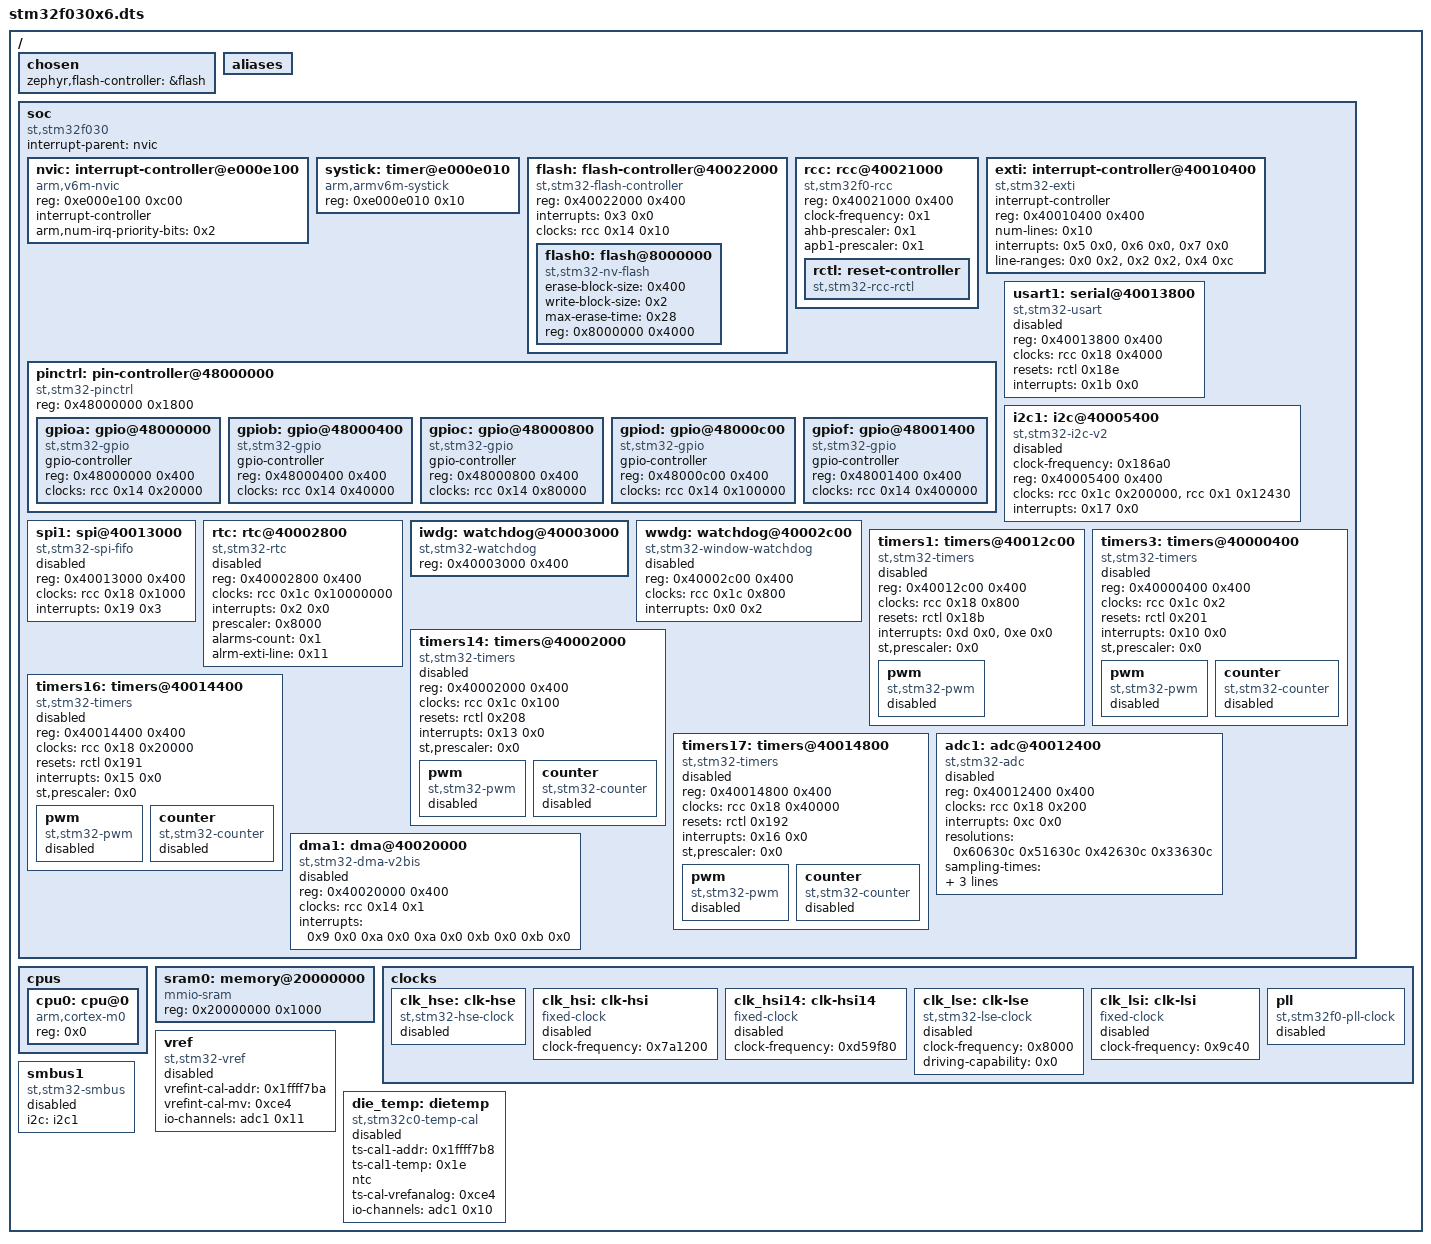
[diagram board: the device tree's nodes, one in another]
/dts-v1/;

/ {
	#address-cells = < 0x1 >;
	#size-cells = < 0x1 >;
	chosen {
		zephyr,flash-controller = &flash;
	};
	aliases {
	};
	soc {
		#address-cells = < 0x1 >;
		#size-cells = < 0x1 >;
		compatible = "st,stm32f030", "st,stm32f0", "simple-bus";
		interrupt-parent = < &nvic >;
		ranges;
		nvic: interrupt-controller@e000e100 {
			#address-cells = < 0x1 >;
			compatible = "arm,v6m-nvic";
			reg = < 0xe000e100 0xc00 >;
			interrupt-controller;
			#interrupt-cells = < 0x2 >;
			arm,num-irq-priority-bits = < 0x2 >;
			phandle = < 0x1 >;
		};
		systick: timer@e000e010 {
			compatible = "arm,armv6m-systick";
			reg = < 0xe000e010 0x10 >;
		};
		flash: flash-controller@40022000 {
			compatible = "st,stm32-flash-controller", "st,stm32f1-flash-controller";
			reg = < 0x40022000 0x400 >;
			interrupts = < 0x3 0x0 >;
			clocks = < &rcc 0x14 0x10 >;
			#address-cells = < 0x1 >;
			#size-cells = < 0x1 >;
			flash0: flash@8000000 {
				compatible = "st,stm32-nv-flash", "soc-nv-flash";
				erase-block-size = < 0x400 >;
				write-block-size = < 0x2 >;
				max-erase-time = < 0x28 >;
				reg = < 0x8000000 0x4000 >;
			};
		};
		rcc: rcc@40021000 {
			compatible = "st,stm32f0-rcc";
			#clock-cells = < 0x2 >;
			reg = < 0x40021000 0x400 >;
			clock-frequency = < 0x1 >;
			ahb-prescaler = < 0x1 >;
			apb1-prescaler = < 0x1 >;
			phandle = < 0x2 >;
			rctl: reset-controller {
				compatible = "st,stm32-rcc-rctl";
				#reset-cells = < 0x1 >;
				phandle = < 0x3 >;
			};
		};
		exti: interrupt-controller@40010400 {
			compatible = "st,stm32-exti";
			interrupt-controller;
			#interrupt-cells = < 0x1 >;
			#address-cells = < 0x1 >;
			reg = < 0x40010400 0x400 >;
			num-lines = < 0x10 >;
			interrupts = < 0x5 0x0 >, < 0x6 0x0 >, < 0x7 0x0 >;
			interrupt-names = "line0-1", "line2-3", "line4-15";
			line-ranges = < 0x0 0x2 >, < 0x2 0x2 >, < 0x4 0xc >;
		};
		pinctrl: pin-controller@48000000 {
			compatible = "st,stm32-pinctrl";
			#address-cells = < 0x1 >;
			#size-cells = < 0x1 >;
			reg = < 0x48000000 0x1800 >;
			gpioa: gpio@48000000 {
				compatible = "st,stm32-gpio";
				gpio-controller;
				#gpio-cells = < 0x2 >;
				reg = < 0x48000000 0x400 >;
				clocks = < &rcc 0x14 0x20000 >;
			};
			gpiob: gpio@48000400 {
				compatible = "st,stm32-gpio";
				gpio-controller;
				#gpio-cells = < 0x2 >;
				reg = < 0x48000400 0x400 >;
				clocks = < &rcc 0x14 0x40000 >;
			};
			gpioc: gpio@48000800 {
				compatible = "st,stm32-gpio";
				gpio-controller;
				#gpio-cells = < 0x2 >;
				reg = < 0x48000800 0x400 >;
				clocks = < &rcc 0x14 0x80000 >;
			};
			gpiod: gpio@48000c00 {
				compatible = "st,stm32-gpio";
				gpio-controller;
				#gpio-cells = < 0x2 >;
				reg = < 0x48000c00 0x400 >;
				clocks = < &rcc 0x14 0x100000 >;
			};
			gpiof: gpio@48001400 {
				compatible = "st,stm32-gpio";
				gpio-controller;
				#gpio-cells = < 0x2 >;
				reg = < 0x48001400 0x400 >;
				clocks = < &rcc 0x14 0x400000 >;
			};
		};
		usart1: serial@40013800 {
			compatible = "st,stm32-usart", "st,stm32-uart";
			reg = < 0x40013800 0x400 >;
			clocks = < &rcc 0x18 0x4000 >;
			resets = < &rctl 0x18e >;
			interrupts = < 0x1b 0x0 >;
			status = "disabled";
		};
		i2c1: i2c@40005400 {
			compatible = "st,stm32-i2c-v2";
			clock-frequency = < 0x186a0 >;
			#address-cells = < 0x1 >;
			#size-cells = < 0x0 >;
			reg = < 0x40005400 0x400 >;
			clocks = < &rcc 0x1c 0x200000 >, < &rcc 0x1 0x12430 >;
			interrupts = < 0x17 0x0 >;
			interrupt-names = "combined";
			status = "disabled";
			phandle = < 0x5 >;
		};
		spi1: spi@40013000 {
			compatible = "st,stm32-spi-fifo", "st,stm32-spi";
			#address-cells = < 0x1 >;
			#size-cells = < 0x0 >;
			reg = < 0x40013000 0x400 >;
			clocks = < &rcc 0x18 0x1000 >;
			interrupts = < 0x19 0x3 >;
			status = "disabled";
		};
		rtc: rtc@40002800 {
			compatible = "st,stm32-rtc";
			reg = < 0x40002800 0x400 >;
			clocks = < &rcc 0x1c 0x10000000 >;
			interrupts = < 0x2 0x0 >;
			prescaler = < 0x8000 >;
			alarms-count = < 0x1 >;
			alrm-exti-line = < 0x11 >;
			status = "disabled";
		};
		iwdg: watchdog@40003000 {
			compatible = "st,stm32-watchdog";
			reg = < 0x40003000 0x400 >;
		};
		wwdg: watchdog@40002c00 {
			compatible = "st,stm32-window-watchdog";
			reg = < 0x40002c00 0x400 >;
			clocks = < &rcc 0x1c 0x800 >;
			interrupts = < 0x0 0x2 >;
			status = "disabled";
		};
		timers1: timers@40012c00 {
			compatible = "st,stm32-timers";
			reg = < 0x40012c00 0x400 >;
			clocks = < &rcc 0x18 0x800 >;
			resets = < &rctl 0x18b >;
			interrupts = < 0xd 0x0 >, < 0xe 0x0 >;
			interrupt-names = "brk_up_trg_com", "cc";
			st,prescaler = < 0x0 >;
			status = "disabled";
			pwm {
				compatible = "st,stm32-pwm";
				status = "disabled";
				#pwm-cells = < 0x3 >;
			};
		};
		timers3: timers@40000400 {
			compatible = "st,stm32-timers";
			reg = < 0x40000400 0x400 >;
			clocks = < &rcc 0x1c 0x2 >;
			resets = < &rctl 0x201 >;
			interrupts = < 0x10 0x0 >;
			interrupt-names = "global";
			st,prescaler = < 0x0 >;
			status = "disabled";
			pwm {
				compatible = "st,stm32-pwm";
				status = "disabled";
				#pwm-cells = < 0x3 >;
			};
			counter {
				compatible = "st,stm32-counter";
				status = "disabled";
			};
		};
		timers14: timers@40002000 {
			compatible = "st,stm32-timers";
			reg = < 0x40002000 0x400 >;
			clocks = < &rcc 0x1c 0x100 >;
			resets = < &rctl 0x208 >;
			interrupts = < 0x13 0x0 >;
			interrupt-names = "global";
			st,prescaler = < 0x0 >;
			status = "disabled";
			pwm {
				compatible = "st,stm32-pwm";
				status = "disabled";
				#pwm-cells = < 0x3 >;
			};
			counter {
				compatible = "st,stm32-counter";
				status = "disabled";
			};
		};
		timers16: timers@40014400 {
			compatible = "st,stm32-timers";
			reg = < 0x40014400 0x400 >;
			clocks = < &rcc 0x18 0x20000 >;
			resets = < &rctl 0x191 >;
			interrupts = < 0x15 0x0 >;
			interrupt-names = "global";
			st,prescaler = < 0x0 >;
			status = "disabled";
			pwm {
				compatible = "st,stm32-pwm";
				status = "disabled";
				#pwm-cells = < 0x3 >;
			};
			counter {
				compatible = "st,stm32-counter";
				status = "disabled";
			};
		};
		timers17: timers@40014800 {
			compatible = "st,stm32-timers";
			reg = < 0x40014800 0x400 >;
			clocks = < &rcc 0x18 0x40000 >;
			resets = < &rctl 0x192 >;
			interrupts = < 0x16 0x0 >;
			interrupt-names = "global";
			st,prescaler = < 0x0 >;
			status = "disabled";
			pwm {
				compatible = "st,stm32-pwm";
				status = "disabled";
				#pwm-cells = < 0x3 >;
			};
			counter {
				compatible = "st,stm32-counter";
				status = "disabled";
			};
		};
		adc1: adc@40012400 {
			compatible = "st,stm32-adc";
			reg = < 0x40012400 0x400 >;
			clocks = < &rcc 0x18 0x200 >;
			interrupts = < 0xc 0x0 >;
			status = "disabled";
			#io-channel-cells = < 0x1 >;
			resolutions = < 0x60630c 0x51630c 0x42630c 0x33630c >;
			sampling-times = < 0x2 0x8 0xe 0x1d 0x2a 0x38 0x48 0xf0 >;
			num-sampling-time-common-channels = < 0x1 >;
			st,adc-sequencer = < 0x0 >;
			phandle = < 0x4 >;
		};
		dma1: dma@40020000 {
			compatible = "st,stm32-dma-v2bis";
			#dma-cells = < 0x2 >;
			reg = < 0x40020000 0x400 >;
			clocks = < &rcc 0x14 0x1 >;
			interrupts = < 0x9 0x0 0xa 0x0 0xa 0x0 0xb 0x0 0xb 0x0 >;
			status = "disabled";
		};
	};
	cpus {
		#address-cells = < 0x1 >;
		#size-cells = < 0x0 >;
		cpu0: cpu@0 {
			device_type = "cpu";
			compatible = "arm,cortex-m0";
			reg = < 0x0 >;
		};
	};
	sram0: memory@20000000 {
		compatible = "mmio-sram";
		reg = < 0x20000000 0x1000 >;
	};
	clocks {
		clk_hse: clk-hse {
			#clock-cells = < 0x0 >;
			compatible = "st,stm32-hse-clock";
			status = "disabled";
		};
		clk_hsi: clk-hsi {
			#clock-cells = < 0x0 >;
			compatible = "fixed-clock";
			clock-frequency = < 0x7a1200 >;
			status = "disabled";
		};
		clk_hsi14: clk-hsi14 {
			#clock-cells = < 0x0 >;
			compatible = "fixed-clock";
			clock-frequency = < 0xd59f80 >;
			status = "disabled";
		};
		clk_lse: clk-lse {
			#clock-cells = < 0x0 >;
			compatible = "st,stm32-lse-clock";
			clock-frequency = < 0x8000 >;
			driving-capability = < 0x0 >;
			status = "disabled";
		};
		clk_lsi: clk-lsi {
			#clock-cells = < 0x0 >;
			compatible = "fixed-clock";
			clock-frequency = < 0x9c40 >;
			status = "disabled";
		};
		pll: pll {
			#clock-cells = < 0x0 >;
			compatible = "st,stm32f0-pll-clock";
			status = "disabled";
		};
	};
	vref: vref {
		compatible = "st,stm32-vref";
		vrefint-cal-addr = < 0x1ffff7ba >;
		vrefint-cal-mv = < 0xce4 >;
		io-channels = < &adc1 0x11 >;
		status = "disabled";
	};
	smbus1: smbus1 {
		compatible = "st,stm32-smbus";
		#address-cells = < 0x1 >;
		#size-cells = < 0x0 >;
		i2c = < &i2c1 >;
		status = "disabled";
	};
	die_temp: dietemp {
		compatible = "st,stm32c0-temp-cal";
		ts-cal1-addr = < 0x1ffff7b8 >;
		ts-cal1-temp = < 0x1e >;
		ntc;
		ts-cal-vrefanalog = < 0xce4 >;
		io-channels = < &adc1 0x10 >;
		status = "disabled";
	};
};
